AUTOSAR XML (schema 00044)
package /ComponentTypes
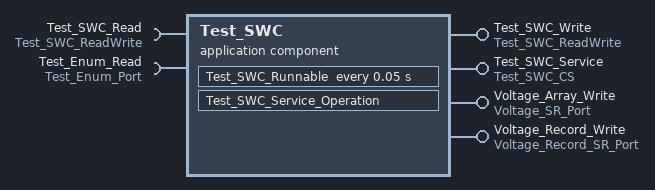
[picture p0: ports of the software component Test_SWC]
  application sw component type Test_SWC
    require port Test_SWC_Read: nonqueued-receiver-com-spec{data-element=Element, init-value=0}, required-interface=Test_SWC_ReadWrite
    4 x provide port:
      Test_SWC_Write: nonqueued-sender-com-spec{data-element=Element, init-value=0}, provided-interface=Test_SWC_ReadWrite
      Test_SWC_Service: server-com-spec{operation=Operation, queue-length=1}, provided-interface=Test_SWC_CS
      Voltage_Array_Write: nonqueued-sender-com-spec{data-element=u16_Signal, init-value=8 x 0}, provided-interface=Voltage_SR_Port
      Voltage_Record_Write: nonqueued-sender-com-spec{data-element=St_Signal, init-value=fields=[ElementConstant:0, ElementConstant_1:0]}, provided-interface=Voltage_Record_SR_Port
    require port Test_Enum_Read: nonqueued-receiver-com-spec{data-element=u8_signal, init-value=0}, required-interface=Test_Enum_Port
    behavior Test_SWC_InternalBehavior
      timing event TMT_Test_SWC_Runnable: start-on-event=Test_SWC_Runnable, period=0.05
      operation invoked event OIT_Test_SWC_Service_Operation_Test_SWC_Service_Operation: start-on-event=Test_SWC_Service_Operation, operation=Test_SWC_Service.Operation
      runnable Test_SWC_Runnable: minimum-start-interval=0.05
        data-receive-point-by-arguments:
          access REC_Test_SWC_Read_Element: accessed-variable=Test_SWC_Read.Element
        data-send-points:
          access SEND_Test_SWC_ReadWrite_Element: accessed-variable=Test_SWC_Write.Element
      runnable Test_SWC_Service_Operation
        data-receive-point-by-arguments:
          access REC_Test_Enum_Read_u8_signal: accessed-variable=Test_Enum_Read.u8_signal
        data-send-points:
          access SEND_Voltage_Record_Write_St_Signal: accessed-variable=Voltage_Record_Write.St_Signal
          access SEND_Voltage_Write_u16_Signal: accessed-variable=Voltage_Array_Write.u16_Signal
  swc implementation Test_SWC_Implementation: behavior=Test_SWC_InternalBehavior
